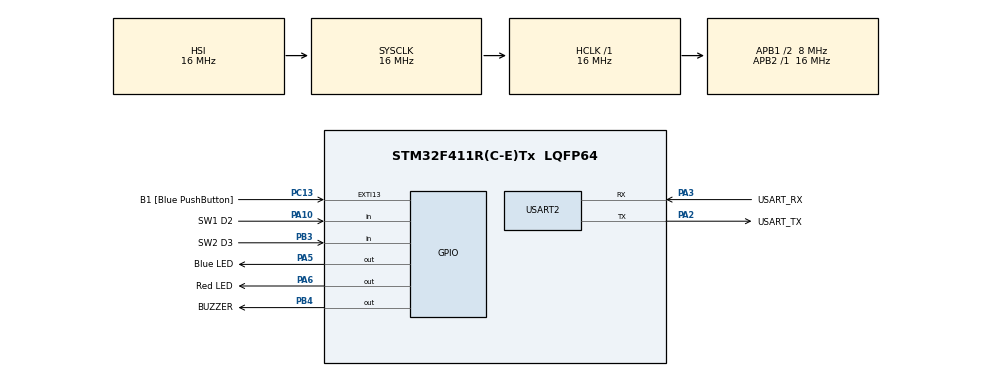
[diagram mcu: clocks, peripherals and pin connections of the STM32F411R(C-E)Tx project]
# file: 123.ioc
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Mcu.Family=STM32F4
Mcu.Name=STM32F411R(C-E)Tx
Mcu.Package=LQFP64
NVIC.PriorityGroup=NVIC_PRIORITYGROUP_0
NVIC.TIM3_IRQn=true\:0\:0\:false\:false\:true\:true\:true\:true
PA10.GPIO_Label=SW1 D2
PA10.GPIO_PuPd=GPIO_NOPULL
PA10.Signal=GPIO_Input
PA13.GPIO_Label=TMS
PA13.Mode=Serial_Wire
PA13.Signal=SYS_JTMS-SWDIO
PA14.GPIO_Label=TCK
PA14.Mode=Serial_Wire
PA14.Signal=SYS_JTCK-SWCLK
PA2.GPIO_Label=USART_TX
PA2.Mode=Asynchronous
PA2.Signal=USART2_TX
PA3.GPIO_Label=USART_RX
PA3.Mode=Asynchronous
PA3.Signal=USART2_RX
PA5.GPIO_Label=Blue LED
PA5.Signal=GPIO_Output
PA6.GPIO_Label=Red LED
PA6.Signal=GPIO_Output
PB3.GPIO_Label=SW2 D3
PB3.Signal=GPIO_Input
PB4.GPIO_Label=BUZZER
PB4.Signal=GPIO_Output
PC13-ANTI_TAMP.GPIO_Label=B1 [Blue PushButton]
PC13-ANTI_TAMP.GPIO_ModeDefaultEXTI=GPIO_MODE_IT_FALLING
PC13-ANTI_TAMP.Signal=GPXTI13
PC14-OSC32_IN.Mode=LSE-External-Oscillator
PC14-OSC32_IN.Signal=RCC_OSC32_IN
PC15-OSC32_OUT.Mode=LSE-External-Oscillator
PC15-OSC32_OUT.Signal=RCC_OSC32_OUT
PH0\ -\ OSC_IN.Mode=HSE-External-Clock-Source
PH0\ -\ OSC_IN.Signal=RCC_OSC_IN
PH1\ -\ OSC_OUT.Mode=HSE-External-Clock-Source
PH1\ -\ OSC_OUT.Signal=RCC_OSC_OUT
ProjectManager.HeapSize=0x200
ProjectManager.StackSize=0x400
ProjectManager.TargetToolchain=STM32CubeIDE
RCC.48MHZClocksFreq_Value=336000000
RCC.AHBFreq_Value=16000000
RCC.APB1CLKDivider=RCC_HCLK_DIV2
RCC.APB1Freq_Value=8000000
RCC.APB1TimFreq_Value=16000000
RCC.APB2Freq_Value=16000000
RCC.APB2TimFreq_Value=16000000
RCC.CortexFreq_Value=16000000
RCC.FLatency-AdvancedSettings=FLASH_LATENCY_0
RCC.HCLKFreq_Value=16000000
RCC.HSE_VALUE=16000000
RCC.HSI_VALUE=16000000
RCC.PLLM=4
RCC.PLLN=336
RCC.PLLP=RCC_PLLP_DIV4
RCC.PLLSourceVirtual=RCC_PLLSOURCE_HSE
RCC.SYSCLKFreq_VALUE=16000000
RCC.VCOOutputFreq_Value=1344000000
TIM3.Period=1000-1
TIM3.Prescaler=16000-1
USART2.VirtualMode=VM_ASYNC
VP_TIM3_VS_ClockSourceINT.Mode=Internal
board=NUCLEO-F411RE

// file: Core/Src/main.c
/* USER CODE BEGIN Header */
/**
  ******************************************************************************
  * @file           : main.c
  * @brief          : Main program body
  ******************************************************************************
  * @attention
  *
  * Copyright (c) 2023 STMicroelectronics.
  * All rights reserved.
  *
  * This software is licensed under terms that can be found in the LICENSE file
  * in the root directory of this software component.
  * If no LICENSE file comes with this software, it is provided AS-IS.
  *
  ******************************************************************************
  */
/* USER CODE END Header */
#include "main.h"

TIM_HandleTypeDef htim3;

UART_HandleTypeDef huart2;

/* USER CODE BEGIN PV */
int isON = 0;
int isTimmer = 1;
/* USER CODE END PV */

void SystemClock_Config(void);
static void MX_GPIO_Init(void);
static void MX_USART2_UART_Init(void);
static void MX_TIM3_Init(void);

int main(void)
{

  /* MCU Configuration--------------------------------------------------------*/

  /* Reset of all peripherals, Initializes the Flash interface and the Systick. */
  HAL_Init();

  /* Configure the system clock */
  SystemClock_Config();

  /* Initialize all configured peripherals */
  MX_GPIO_Init();
  MX_USART2_UART_Init();
  MX_TIM3_Init();
  /* USER CODE BEGIN 2 */
  HAL_TIM_Base_Start_IT(&htim3);
  /* USER CODE END 2 */

  /* Infinite loop */
  while (1)
  {
	  int value = HAL_GPIO_ReadPin(GPIOB, GPIO_PIN_3);
	  if(value == 0){
		  HAL_GPIO_WritePin(GPIOA, GPIO_PIN_6, 1);
	  }
	  else{
		  HAL_GPIO_WritePin(GPIOA, GPIO_PIN_6, 0);
	  }
  }
}

void SystemClock_Config(void)
{
  RCC_OscInitTypeDef RCC_OscInitStruct = {0};
  RCC_ClkInitTypeDef RCC_ClkInitStruct = {0};

  /** Configure the main internal regulator output voltage
  */
  __HAL_RCC_PWR_CLK_ENABLE();
  __HAL_PWR_VOLTAGESCALING_CONFIG(PWR_REGULATOR_VOLTAGE_SCALE1);

  /** Initializes the RCC Oscillators according to the specified parameters
  * in the RCC_OscInitTypeDef structure.
  */
  RCC_OscInitStruct.OscillatorType = RCC_OSCILLATORTYPE_HSI;
  RCC_OscInitStruct.HSIState = RCC_HSI_ON;
  RCC_OscInitStruct.HSICalibrationValue = RCC_HSICALIBRATION_DEFAULT;
  RCC_OscInitStruct.PLL.PLLState = RCC_PLL_NONE;
  if (HAL_RCC_OscConfig(&RCC_OscInitStruct) != HAL_OK)
  {
    Error_Handler();
  }

  /** Initializes the CPU, AHB and APB buses clocks
  */
  RCC_ClkInitStruct.ClockType = RCC_CLOCKTYPE_HCLK|RCC_CLOCKTYPE_SYSCLK
                              |RCC_CLOCKTYPE_PCLK1|RCC_CLOCKTYPE_PCLK2;
  RCC_ClkInitStruct.SYSCLKSource = RCC_SYSCLKSOURCE_HSI;
  RCC_ClkInitStruct.AHBCLKDivider = RCC_SYSCLK_DIV1;
  RCC_ClkInitStruct.APB1CLKDivider = RCC_HCLK_DIV2;
  RCC_ClkInitStruct.APB2CLKDivider = RCC_HCLK_DIV1;

  if (HAL_RCC_ClockConfig(&RCC_ClkInitStruct, FLASH_LATENCY_0) != HAL_OK)
  {
    Error_Handler();
  }
}

static void MX_TIM3_Init(void)
{

  TIM_ClockConfigTypeDef sClockSourceConfig = {0};
  TIM_MasterConfigTypeDef sMasterConfig = {0};

  htim3.Instance = TIM3;
  htim3.Init.Prescaler = 16000-1;
  htim3.Init.CounterMode = TIM_COUNTERMODE_UP;
  htim3.Init.Period = 1000-1;
  htim3.Init.ClockDivision = TIM_CLOCKDIVISION_DIV1;
  htim3.Init.AutoReloadPreload = TIM_AUTORELOAD_PRELOAD_DISABLE;
  if (HAL_TIM_Base_Init(&htim3) != HAL_OK)
  {
    Error_Handler();
  }
  sClockSourceConfig.ClockSource = TIM_CLOCKSOURCE_INTERNAL;
  if (HAL_TIM_ConfigClockSource(&htim3, &sClockSourceConfig) != HAL_OK)
  {
    Error_Handler();
  }
  sMasterConfig.MasterOutputTrigger = TIM_TRGO_RESET;
  sMasterConfig.MasterSlaveMode = TIM_MASTERSLAVEMODE_DISABLE;
  if (HAL_TIMEx_MasterConfigSynchronization(&htim3, &sMasterConfig) != HAL_OK)
  {
    Error_Handler();
  }

}

static void MX_USART2_UART_Init(void)
{

  huart2.Instance = USART2;
  huart2.Init.BaudRate = 115200;
  huart2.Init.WordLength = UART_WORDLENGTH_8B;
  huart2.Init.StopBits = UART_STOPBITS_1;
  huart2.Init.Parity = UART_PARITY_NONE;
  huart2.Init.Mode = UART_MODE_TX_RX;
  huart2.Init.HwFlowCtl = UART_HWCONTROL_NONE;
  huart2.Init.OverSampling = UART_OVERSAMPLING_16;
  if (HAL_UART_Init(&huart2) != HAL_OK)
  {
    Error_Handler();
  }

}

static void MX_GPIO_Init(void)
{
  GPIO_InitTypeDef GPIO_InitStruct = {0};

  /* GPIO Ports Clock Enable */
  __HAL_RCC_GPIOC_CLK_ENABLE();
  __HAL_RCC_GPIOH_CLK_ENABLE();
  __HAL_RCC_GPIOA_CLK_ENABLE();
  __HAL_RCC_GPIOB_CLK_ENABLE();

  /*Configure GPIO pin Output Level */
  HAL_GPIO_WritePin(GPIOA, Blue_LED_Pin|Red_LED_Pin, GPIO_PIN_RESET);

  /*Configure GPIO pin Output Level */
  HAL_GPIO_WritePin(BUZZER_GPIO_Port, BUZZER_Pin, GPIO_PIN_RESET);

  /*Configure GPIO pin : B1_Pin */
  GPIO_InitStruct.Pin = B1_Pin;
  GPIO_InitStruct.Mode = GPIO_MODE_IT_FALLING;
  GPIO_InitStruct.Pull = GPIO_NOPULL;
  HAL_GPIO_Init(B1_GPIO_Port, &GPIO_InitStruct);

  /*Configure GPIO pins : Blue_LED_Pin Red_LED_Pin */
  GPIO_InitStruct.Pin = Blue_LED_Pin|Red_LED_Pin;
  GPIO_InitStruct.Mode = GPIO_MODE_OUTPUT_PP;
  GPIO_InitStruct.Pull = GPIO_NOPULL;
  GPIO_InitStruct.Speed = GPIO_SPEED_FREQ_LOW;
  HAL_GPIO_Init(GPIOA, &GPIO_InitStruct);

  /*Configure GPIO pin : SW1_D2_Pin */
  GPIO_InitStruct.Pin = SW1_D2_Pin;
  GPIO_InitStruct.Mode = GPIO_MODE_INPUT;
  GPIO_InitStruct.Pull = GPIO_NOPULL;
  HAL_GPIO_Init(SW1_D2_GPIO_Port, &GPIO_InitStruct);

  /*Configure GPIO pin : SW2_D3_Pin */
  GPIO_InitStruct.Pin = SW2_D3_Pin;
  GPIO_InitStruct.Mode = GPIO_MODE_INPUT;
  GPIO_InitStruct.Pull = GPIO_NOPULL;
  HAL_GPIO_Init(SW2_D3_GPIO_Port, &GPIO_InitStruct);

  /*Configure GPIO pin : BUZZER_Pin */
  GPIO_InitStruct.Pin = BUZZER_Pin;
  GPIO_InitStruct.Mode = GPIO_MODE_OUTPUT_PP;
  GPIO_InitStruct.Pull = GPIO_NOPULL;
  GPIO_InitStruct.Speed = GPIO_SPEED_FREQ_LOW;
  HAL_GPIO_Init(BUZZER_GPIO_Port, &GPIO_InitStruct);

}

/* USER CODE BEGIN 4 */
void HAL_TIM_PeriodElapsedCallback(TIM_HandleTypeDef *htim){
	if(htim->Instance==TIM3){
		if(isTimmer == 1){
			HAL_GPIO_TogglePin(GPIOA,GPIO_PIN_5);
		}
	}
}
/* USER CODE END 4 */

void Error_Handler(void)
{
  __disable_irq();
  while (1)
  {
  }
}
